# M460 register map
File version: 1.0
Registers are 32-bit, read-write, reset 0x0 unless marked. A register's access mark holds for its fields unless they carry their own. Offsets are from the block's base; [hi:lo] are bit positions; {n}, {i} and the like mark numbered series; 'fields as' and 'values as' point back to an identical list.

## CRC — CRC Register Map
Base 0x40031000
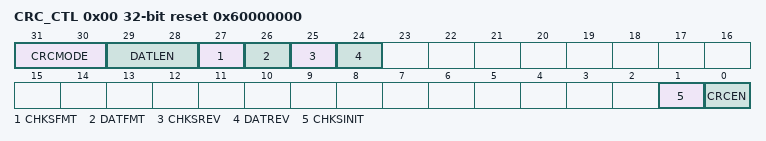
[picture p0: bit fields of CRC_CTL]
0x00 CRC_CTL reset 0x60000000 — CRC Control Register
  [31:30] CRCMODE — CRC Polynomial Mode. This field indicates the CRC operation polynomial mode. Note: User must program the polynomial value in CRC_POLYNOMIAL register to specify the polynomial used for CRC calculation.
    0=CRC-16 Polynomial mode; 1=CRC-8 Polynomial mode; 2=CRC-16 Polynomial mode; 3=CRC-32 Polynomial mode
  [29:28] DATLEN — CPU Write Data Length. This field indicates the write data length. Note: When the write data length is 8-bit mode, the valid data in CRC_DAT register is only DATA[7:0] bits; if the write data length is 16-bit mode, the valid data in CRC_DAT register is only DATA[15:0].
    0=Data length is 8-bit mode; 1=Data length is 16-bit mode; 2=Data length is 32-bit mode
  [27] CHKSFMT — Checksum 1's Complement. This bit is used to enable the 1's complement function for checksum result in CRC_CHECKSUM register.
    0=1's complement for CRC checksum Disabled; 1=1's complement for CRC checksum Enabled
  [26] DATFMT — Write Data 1's Complement. This bit is used to enable the 1's complement function for write data value in CRC_DAT register.
    0=1's complement for CRC writes data in Disabled; 1=1's complement for CRC writes data in Enabled
  [25] CHKSREV — Checksum Bit Order Reverse. This bit is used to enable the bit order reverse function for checksum result in CRC_CHECKSUM register. Note: If the checksum result is 0xDD7B0F2E, the bit order reverse for CRC checksum is 0x74F0DEBB.
    0=Bit order reverse for CRC checksum Disabled; 1=Bit order reverse for CRC checksum Enabled
  [24] DATREV — Write Data Bit Order Reverse. This bit is used to enable the bit order reverse function per byte for write data value in CRC_DAT register. Note: If the write data is 0xAABBCCDD, the bit order reverse for CRC write data in is 0x55DD33BB.
    0=Bit order reversed for CRC write data in Disabled; 1=Bit order reversed for CRC write data in Enabled (per byte)
  [1] CHKSINIT wo — Checksum Initialization (Write Only). Note: This bit will be cleared automatically.
    0=No effect; 1=Initial checksum value by auto reload CRC_SEED register value to CRC_CHECKSUM register value
  [0] CRCEN — CRC Channel Enable Bit
    0=No effect; 1=CRC operation Enabled
0x04 CRC_DAT — CRC Write Data Register
  [31:0] DATA — CRC Write Data Bits. User can write data directly by CPU mode or use PDMA function to write data to this field to perform CRC operation. Note: When the write data length is 8-bit mode, the valid data in CRC_DAT register is only DATA[7:0] bits; if the write data length is 16-bit mode, the valid data in CRC_DAT register is only DATA[15:0].
0x08 CRC_SEED reset 0xFFFFFFFF
  [31:0] SEED — CRC Seed Value. This field indicates the CRC seed value. Note: This field will be reloaded as checksum initial value (CRC_CHECKSUM register) after performing CHKSINIT (CRC_CTL[1]).
0x0C CRC_CHECKSUM ro reset 0xFFFFFFFF
  [31:0] CHECKSUM — CRC Checksum Results. This field indicates the CRC checksum result.
0x10 CRC_POLYNOMIAL
  [31:0] POLYNOMIAL — CRC Polynomial Value. This field indicates the value of CRC polynomial.

## PRNG — CRYPTO Register Map
Base 0x40032008
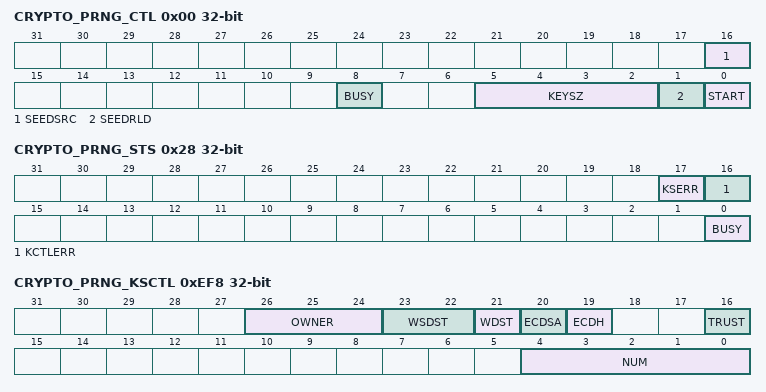
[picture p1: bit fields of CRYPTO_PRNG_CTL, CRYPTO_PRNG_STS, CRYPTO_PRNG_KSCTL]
0x00 CRYPTO_PRNG_CTL — PRNG Control Register
  [16] SEEDSRC — Seed Source. Note: When SEEDRLD is set to 0, this bit (SEEDSRC) is meaningless.
    0=Seed is from TRNG; 1=Seed is from PRNG seed register
  [8] BUSY ro — PRNG Busy (Read Only)
    0=PRNG engine is idle; 1=PRNG engine is generating CRYPTO_PRNG_KEYx
  [5:2] KEYSZ — PRNG Generate Key Size. Note: 283~571 bits are only generated for key store.
    0=128 bits; 1=163 bits; 2=192 bits; 3=224 bits; 4=233 bits; 5=255 bits; 6=256 bits; 7=283 bits (only for KS); 8=384 bits (only for KS); 9=409 bits (only for KS); 10=512 bits (only for KS); 11=521 bits (only for KS); 12=571 bits (only for KS)
  [1] SEEDRLD — Reload New Seed for PRNG Engine
    0=Generating key based on the current seed; 1=Reload new seed
  [0] START — Start PRNG Engine
    0=Stop PRNG engine; 1=Generate new key and store the new key to register CRYPTO_PRNG_KEYx, which will be cleared when the new key is generated
0x04 CRYPTO_PRNG_SEED wo reset not defined — Seed for PRNG
  [31:0] SEED — Seed for PRNG (Write Only). The bits store the seed for PRNG engine. Note: In TRNG+PRNG mode, the seed is from TRNG engine, and it will not be stored in this register.
{0x8+4i} CRYPTO_PRNG_KEY{i} ro reset not defined (i=0..7) — PRNG Generated Key{i}
  [31:0] KEY — Store PRNG Generated Key (Read Only). The bits store the key that is generated by PRNG.
0x28 CRYPTO_PRNG_STS ro — PRNG Status Register
  [17] KSERR — PRNG Access Key Store Error Flag
    0=No error; 1=Access key store failed
  [16] KCTLERR — PRNG Key Control Register Error Flag
    0=No error; 1=PRNG key control error. When PRNG execute ECDSA or ECDH, but PRNG seed not from TRNG or key is not written to the SRAM of key store (WSDST, CRYPTO_PRNG_KSCTL[23:22] is not equal to '00')
  [0] BUSY — PRNG Busy Flag
    values as CRYPTO_PRNG_CTL.BUSY
0xEF8 CRYPTO_PRNG_KSCTL wo — PRNG Key Control Register
  [26:24] OWNER — Write Key Owner Selection Bits
    0=Only for AES use; 1=Only for HMAC engine use; 4=Only for ECC engine use; 5=Only for CPU engine use
  [23:22] WSDST — Write Key Store Destination
    0=Key is written to the SRAM of key store; 1=Key is written to the Flash of key store; 2=key is written to the OTP of key store
  [21] WDST — Write Key Destination
    0=Key is written to registers CRYPTO_PRNG_KEYx; 1=Key is written to key store
  [20] ECDSA — ECDSA Control Bit. Note: When ECDSA was set to '1', 1. PRNG seed must from TRNG and key is must written to the SRAM of key store (WSDST, CRYPTO_PRNG_KSCTL[23:22] must set to '00'). Otherwise, KCTLERR will become '1'(CRYPTO_PRNG_KSSTS[16]). 2. Key must in the interval [1, n-1] (the parameter n is from ECC). The value of n cannot be 0 or 1, otherwise, PRNG will always keep busy.
    1=Key is written to key store and used in ECDSA
  [19] ECDH — ECDH Control Bit. Note: When ECDH was set to '1', 1. PRNG seed must from TRNG and key is must written to the SRAM of key store (WSDST, CRYPTO_PRNG_KSCTL[23:22] must set to '00'). Otherwise, KCTLERR will become '1'(CRYPTO_PRNG_KSSTS[16]).2. Key must in the interval [1, n-1] (the parameter n is from ECC). The value of n cannot be 0 or 1, otherwise, PRNG will always keep busy.
    1=Key is written to key store and used in ECDH
  [16] TRUST — Write Key Trust Selection Bit
    0=Set written key as the non-secure key; 1=Set written key as the secure key
  [4:0] NUM — Write Key Number. The key number is sent to key store. Note: Only for destination Is OTP of key store.
0xEFC CRYPTO_PRNG_KSSTS ro — PRNG Key Status Register
  [4:0] NUM — Key Number. The key number is generated by key store
